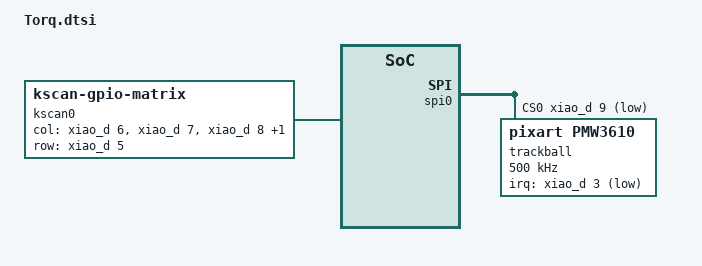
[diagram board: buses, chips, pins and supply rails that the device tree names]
&spi0 {
    status = "okay";
    cs-gpios =  <&xiao_d 9 GPIO_ACTIVE_LOW>, <&xiao_d 10 GPIO_ACTIVE_LOW>;
    pinctrl-0 = <&spi0_default>;
    pinctrl-1 = <&spi0_sleep>;
    pinctrl-names = "default", "sleep";
    compatible = "nordic,nrf-spim";

    trackball: pd@0 {
        status = "okay";
        compatible = "pixart,pmw3610";
        reg = <0>;
  	    cpi = <600>;
        spi-max-frequency = <500000>;
        evt-type = <INPUT_EV_REL>;
        x-input-code = <INPUT_REL_X>;
        y-input-code = <INPUT_REL_Y>;
        irq-gpios = <&xiao_d 3 (GPIO_ACTIVE_LOW | GPIO_PULL_UP)>;
    };
};

/ {
    kscan0: kscan {
        compatible = "zmk,kscan-gpio-matrix";
        wakeup-source;
        diode-direction = "col2row";
        col-gpios
            = <&xiao_d 6 GPIO_ACTIVE_HIGH>
            , <&xiao_d 7 GPIO_ACTIVE_HIGH>
            , <&xiao_d 8 GPIO_ACTIVE_HIGH>
            , <&xiao_d 9 GPIO_ACTIVE_HIGH>
            ;
        row-gpios
            = <&xiao_d 5 (GPIO_ACTIVE_HIGH | GPIO_PULL_DOWN)>
            ;
    };
};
